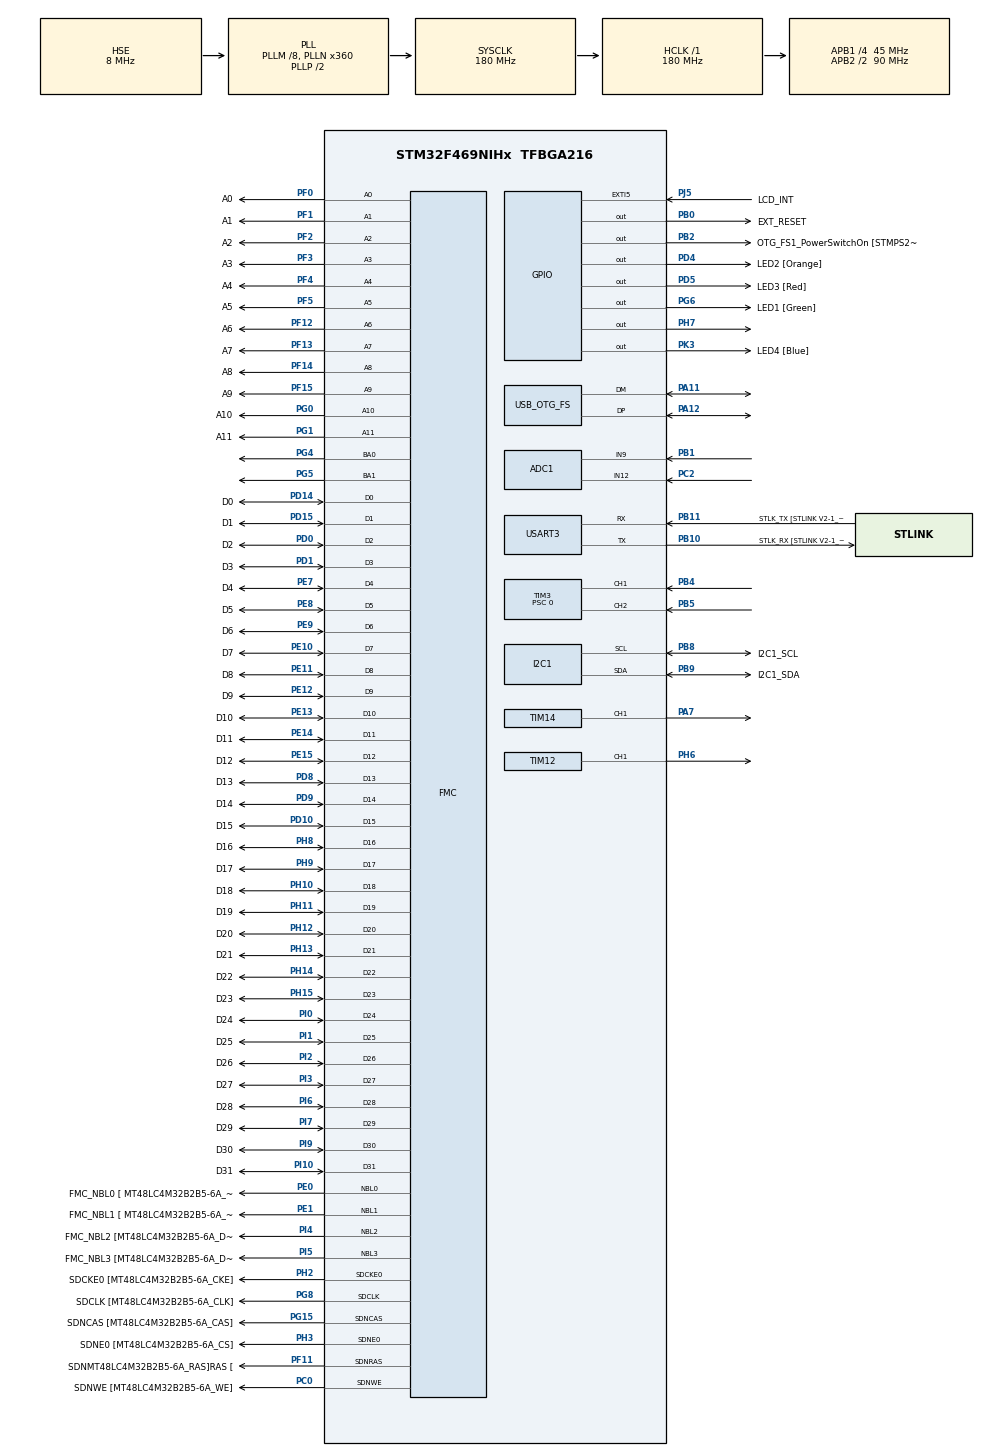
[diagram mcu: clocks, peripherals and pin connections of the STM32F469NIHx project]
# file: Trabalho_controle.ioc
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ADC1.Channel-0\#ChannelRegularConversion=ADC_CHANNEL_9
ADC1.Channel-1\#ChannelRegularConversion=ADC_CHANNEL_12
ADC1.ContinuousConvMode=ENABLE
ADC1.DMAContinuousRequests=ENABLE
ADC1.NbrOfConversion=2
ADC1.NbrOfConversionFlag=1
ADC1.Rank-0\#ChannelRegularConversion=1
ADC1.Rank-1\#ChannelRegularConversion=2
ADC1.SamplingTime-0\#ChannelRegularConversion=ADC_SAMPLETIME_480CYCLES
ADC1.SamplingTime-1\#ChannelRegularConversion=ADC_SAMPLETIME_480CYCLES
ADC1.ScanConvMode=ENABLE
ADC1.master=1
DMA2D.ColorMode=DMA2D_OUTPUT_RGB565
DSIHOST.BTA_FlowControl=__NULL
DSIHOST.ClockLaneHS2LPTime=35
DSIHOST.ClockLaneLP2HSTime=35
DSIHOST.DataLaneHS2LPTime=35
DSIHOST.DataLaneLP2HSTime=35
DSIHOST.LPCommandEnable=DSI_LP_COMMAND_ENABLE
DSIHOST.LPHorizontalBackPorchEnable=DSI_LP_HBP_ENABLE
DSIHOST.LPHorizontalFrontPorchEnable=DSI_LP_HFP_ENABLE
DSIHOST.LPLargestPacketSize=16
DSIHOST.LPVerticalActiveEnable=DSI_LP_VACT_ENABLE
DSIHOST.LPVerticalBackPorchEnable=DSI_LP_VBP_ENABLE
DSIHOST.LPVerticalFrontPorchEnable=DSI_LP_VFP_ENABLE
DSIHOST.LPVerticalSyncActiveEnable=DSI_LP_VSYNC_ENABLE
DSIHOST.Mode=DSI_VID_MODE_BURST
DSIHOST.NumberOfLanes=DSI_TWO_DATA_LANES
DSIHOST.PacketSize=800
DSIHOST.StopWaitTime=10
DSIHOST_CKN.GPIO_Label=DSI_CK_N
DSIHOST_CKN.Mode=DSIHost_Video
DSIHOST_CKN.Signal=DSIHOST_CKN
DSIHOST_CKP.GPIO_Label=DSI_CK_P
DSIHOST_CKP.Mode=DSIHost_Video
DSIHOST_CKP.Signal=DSIHOST_CKP
DSIHOST_D0N.GPIO_Label=DSI_D0_N
DSIHOST_D0N.Mode=DSIHost_Video
DSIHOST_D0N.Signal=DSIHOST_D0N
DSIHOST_D0P.GPIO_Label=DSI_D0_P
DSIHOST_D0P.Mode=DSIHost_Video
DSIHOST_D0P.Signal=DSIHOST_D0P
DSIHOST_D1N.GPIO_Label=DSI_D1_N
DSIHOST_D1N.Mode=DSIHost_Video
DSIHOST_D1N.Signal=DSIHOST_D1N
DSIHOST_D1P.GPIO_Label=DSI_D1_P
DSIHOST_D1P.Mode=DSIHost_Video
DSIHOST_D1P.Signal=DSIHOST_D1P
Dma.ADC1.1.Direction=DMA_PERIPH_TO_MEMORY
Dma.ADC1.1.FIFOMode=DMA_FIFOMODE_DISABLE
Dma.ADC1.1.Instance=DMA2_Stream4
Dma.ADC1.1.MemDataAlignment=DMA_MDATAALIGN_WORD
Dma.ADC1.1.MemInc=DMA_MINC_ENABLE
Dma.ADC1.1.Mode=DMA_CIRCULAR
Dma.ADC1.1.PeriphDataAlignment=DMA_PDATAALIGN_WORD
Dma.ADC1.1.PeriphInc=DMA_PINC_DISABLE
Dma.ADC1.1.Priority=DMA_PRIORITY_HIGH
Dma.MEMTOMEM.0.Direction=DMA_MEMORY_TO_MEMORY
Dma.MEMTOMEM.0.FIFOMode=DMA_FIFOMODE_ENABLE
Dma.MEMTOMEM.0.FIFOThreshold=DMA_FIFO_THRESHOLD_FULL
Dma.MEMTOMEM.0.Instance=DMA2_Stream0
Dma.MEMTOMEM.0.MemBurst=DMA_MBURST_SINGLE
Dma.MEMTOMEM.0.MemDataAlignment=DMA_MDATAALIGN_WORD
Dma.MEMTOMEM.0.MemInc=DMA_MINC_ENABLE
Dma.MEMTOMEM.0.Mode=DMA_NORMAL
Dma.MEMTOMEM.0.PeriphBurst=DMA_PBURST_SINGLE
Dma.MEMTOMEM.0.PeriphDataAlignment=DMA_PDATAALIGN_WORD
Dma.MEMTOMEM.0.PeriphInc=DMA_PINC_ENABLE
Dma.MEMTOMEM.0.Priority=DMA_PRIORITY_LOW
Dma.Request0=MEMTOMEM
Dma.Request1=ADC1
FMC.CASLatency1=FMC_SDRAM_CAS_LATENCY_3
FMC.ExitSelfRefreshDelay1=7
FMC.LoadToActiveDelay1=2
FMC.RCDDelay1=2
FMC.RPDelay1=2
FMC.RPDelay2=2
FMC.ReadBurst1=FMC_SDRAM_RBURST_ENABLE
FMC.ReadBurst2=FMC_SDRAM_RBURST_ENABLE
FMC.RowCycleDelay1=7
FMC.RowCycleDelay2=7
FMC.SDClockPeriod1=FMC_SDRAM_CLOCK_PERIOD_2
FMC.SDClockPeriod2=FMC_SDRAM_CLOCK_PERIOD_2
FMC.SelfRefreshTime1=4
FMC.WriteRecoveryTime1=3
LTDC.ActiveW=800
LTDC.Alpha_L0=255
LTDC.BlendingFactor1_L0=LTDC_BLENDING_FACTOR1_PAxCA
LTDC.BlendingFactor2_L0=LTDC_BLENDING_FACTOR2_PAxCA
LTDC.FBStartAdress_L0=0xC0000000
LTDC.HBP=34
LTDC.HFP=34
LTDC.HSPolarity=LTDC_HSPOLARITY_AH
LTDC.HSync=2
LTDC.ImageHeight_L0=480
LTDC.ImageWidth_L0=800
LTDC.Layers=0
LTDC.PixelFormat_L0=LTDC_PIXEL_FORMAT_RGB565
LTDC.VBP=150
LTDC.VFP=150
LTDC.VSPolarity=LTDC_VSPOLARITY_AH
LTDC.VSync=120
LTDC.WindowX1_L0=800
LTDC.WindowY1_L0=480
Mcu.Family=STM32F4
Mcu.Name=STM32F469NIHx
Mcu.Package=TFBGA216
NVIC.DMA2_Stream0_IRQn=true\:0\:0\:false\:false\:true\:true\:true\:true
NVIC.DMA2_Stream4_IRQn=true\:0\:0\:false\:false\:true\:false\:true\:true
NVIC.DSI_IRQn=true\:0\:0\:false\:false\:true\:true\:true\:true
NVIC.LTDC_IRQn=true\:0\:0\:false\:false\:true\:true\:true\:true
NVIC.OTG_FS_IRQn=true\:0\:0\:false\:false\:true\:false\:true\:true
NVIC.PriorityGroup=NVIC_PRIORITYGROUP_4
PA0/WKUP.GPIO_Label=WAKEUP [B2]
PA0/WKUP.Mode=SYS_WakeUp0
PA0/WKUP.Signal=SYS_WKUP
PA11.Mode=Device_Only
PA11.Signal=USB_OTG_FS_DM
PA12.Mode=Device_Only
PA12.Signal=USB_OTG_FS_DP
PA13.GPIO_Label=SWDIO
PA13.Mode=Serial_Wire
PA13.Signal=SYS_JTMS-SWDIO
PA14.GPIO_Label=SWCLK
PA14.Mode=Serial_Wire
PA14.Signal=SYS_JTCK-SWCLK
PA7.Signal=S_TIM14_CH1
PB0.GPIO_Label=EXT_RESET
PB0.GPIO_ModeDefaultOutputPP=GPIO_MODE_OUTPUT_PP
PB0.GPIO_PuPd=GPIO_NOPULL
PB0.GPIO_Speed=GPIO_SPEED_FREQ_LOW
PB0.Signal=GPIO_Output
PB1.Signal=ADCx_IN9
PB10.GPIO_Label=STLK_RX [STLINK V2-1_U2_RX]
PB10.GPIO_Mode=GPIO_MODE_AF_PP
PB10.GPIO_PuPd=GPIO_PULLUP
PB10.GPIO_Speed=GPIO_SPEED_FREQ_VERY_HIGH
PB10.Mode=Asynchronous
PB10.Signal=USART3_TX
PB11.GPIO_Label=STLK_TX [STLINK V2-1_U2_TX]
PB11.GPIO_Mode=GPIO_MODE_AF_PP
PB11.GPIO_PuPd=GPIO_PULLUP
PB11.GPIO_Speed=GPIO_SPEED_FREQ_VERY_HIGH
PB11.Mode=Asynchronous
PB11.Signal=USART3_RX
PB2/BOOT1.GPIO_Label=OTG_FS1_PowerSwitchOn [STMPS2151STR_En]
PB2/BOOT1.GPIO_ModeDefaultOutputPP=GPIO_MODE_OUTPUT_PP
PB2/BOOT1.GPIO_PuPd=GPIO_NOPULL
PB2/BOOT1.GPIO_Speed=GPIO_SPEED_FREQ_LOW
PB2/BOOT1.Signal=GPIO_Output
PB4.GPIO_PuPd=GPIO_NOPULL
PB4.GPIO_Speed=GPIO_SPEED_FREQ_VERY_HIGH
PB4.Signal=S_TIM3_CH1
PB5.GPIO_PuPd=GPIO_NOPULL
PB5.GPIO_Speed=GPIO_SPEED_FREQ_VERY_HIGH
PB5.Signal=S_TIM3_CH2
PB8.GPIO_Label=I2C1_SCL
PB8.GPIO_Mode=GPIO_MODE_AF_OD
PB8.GPIO_Pu=GPIO_PULLUP
PB8.GPIO_Speed=GPIO_SPEED_FREQ_VERY_HIGH
PB8.Mode=I2C
PB8.Signal=I2C1_SCL
PB9.GPIO_Label=I2C1_SDA
PB9.GPIO_Mode=GPIO_MODE_AF_OD
PB9.GPIO_Pu=GPIO_PULLUP
PB9.GPIO_Speed=GPIO_SPEED_FREQ_VERY_HIGH
PB9.Mode=I2C
PB9.Signal=I2C1_SDA
PC0.GPIO_Label=SDNWE [MT48LC4M32B2B5-6A_WE]
PC0.GPIO_Mode=GPIO_MODE_AF_PP
PC0.GPIO_PuPd=GPIO_NOPULL
PC0.GPIO_Speed_High_Default=GPIO_SPEED_FREQ_VERY_HIGH
PC0.Signal=FMC_SDNWE
PC14/OSC32_IN.Mode=LSE-External-Oscillator
PC14/OSC32_IN.Signal=RCC_OSC32_IN
PC15/OSC32_OUT.Mode=LSE-External-Oscillator
PC15/OSC32_OUT.Signal=RCC_OSC32_OUT
PC2.Signal=ADCx_IN12
PD0.GPIO_Label=D2
PD0.GPIO_Mode=GPIO_MODE_AF_PP
PD0.GPIO_PuPd=GPIO_NOPULL
PD0.GPIO_Speed_High_Default=GPIO_SPEED_FREQ_VERY_HIGH
PD0.Signal=FMC_D2_DA2
PD1.GPIO_Label=D3
PD1.GPIO_Mode=GPIO_MODE_AF_PP
PD1.GPIO_PuPd=GPIO_NOPULL
PD1.GPIO_Speed_High_Default=GPIO_SPEED_FREQ_VERY_HIGH
PD1.Signal=FMC_D3_DA3
PD10.GPIO_Label=D15
PD10.GPIO_Mode=GPIO_MODE_AF_PP
PD10.GPIO_PuPd=GPIO_NOPULL
PD10.GPIO_Speed_High_Default=GPIO_SPEED_FREQ_VERY_HIGH
PD10.Signal=FMC_D15_DA15
PD14.GPIO_Label=D0
PD14.GPIO_Mode=GPIO_MODE_AF_PP
PD14.GPIO_PuPd=GPIO_NOPULL
PD14.GPIO_Speed_High_Default=GPIO_SPEED_FREQ_VERY_HIGH
PD14.Signal=FMC_D0_DA0
PD15.GPIO_Label=D1
PD15.GPIO_Mode=GPIO_MODE_AF_PP
PD15.GPIO_PuPd=GPIO_NOPULL
PD15.GPIO_Speed_High_Default=GPIO_SPEED_FREQ_VERY_HIGH
PD15.Signal=FMC_D1_DA1
PD4.GPIO_Label=LED2 [Orange]
PD4.GPIO_ModeDefaultOutputPP=GPIO_MODE_OUTPUT_OD
PD4.GPIO_PuPd=GPIO_NOPULL
PD4.GPIO_Speed=GPIO_SPEED_FREQ_LOW
PD4.Signal=GPIO_Output
PD5.GPIO_Label=LED3 [Red]
PD5.GPIO_ModeDefaultOutputPP=GPIO_MODE_OUTPUT_OD
PD5.GPIO_PuPd=GPIO_NOPULL
PD5.GPIO_Speed=GPIO_SPEED_FREQ_LOW
PD5.Signal=GPIO_Output
PD8.GPIO_Label=D13
PD8.GPIO_Mode=GPIO_MODE_AF_PP
PD8.GPIO_PuPd=GPIO_NOPULL
PD8.GPIO_Speed_High_Default=GPIO_SPEED_FREQ_VERY_HIGH
PD8.Signal=FMC_D13_DA13
PD9.GPIO_Label=D14
PD9.GPIO_Mode=GPIO_MODE_AF_PP
PD9.GPIO_PuPd=GPIO_NOPULL
PD9.GPIO_Speed_High_Default=GPIO_SPEED_FREQ_VERY_HIGH
PD9.Signal=FMC_D14_DA14
PE0.GPIO_Label=FMC_NBL0 [ MT48LC4M32B2B5-6A_DQM0]
PE0.GPIO_Mode=GPIO_MODE_AF_PP
PE0.GPIO_PuPd=GPIO_NOPULL
PE0.GPIO_Speed_High_Default=GPIO_SPEED_FREQ_VERY_HIGH
PE0.Signal=FMC_NBL0
PE1.GPIO_Label=FMC_NBL1 [ MT48LC4M32B2B5-6A_DQM1]
PE1.GPIO_Mode=GPIO_MODE_AF_PP
PE1.GPIO_PuPd=GPIO_NOPULL
PE1.GPIO_Speed_High_Default=GPIO_SPEED_FREQ_VERY_HIGH
PE1.Signal=FMC_NBL1
PE10.GPIO_Label=D7
PE10.GPIO_Mode=GPIO_MODE_AF_PP
PE10.GPIO_PuPd=GPIO_NOPULL
PE10.GPIO_Speed_High_Default=GPIO_SPEED_FREQ_VERY_HIGH
PE10.Signal=FMC_D7_DA7
PE11.GPIO_Label=D8
PE11.GPIO_Mode=GPIO_MODE_AF_PP
PE11.GPIO_PuPd=GPIO_NOPULL
PE11.GPIO_Speed_High_Default=GPIO_SPEED_FREQ_VERY_HIGH
PE11.Signal=FMC_D8_DA8
PE12.GPIO_Label=D9
PE12.GPIO_Mode=GPIO_MODE_AF_PP
PE12.GPIO_PuPd=GPIO_NOPULL
PE12.GPIO_Speed_High_Default=GPIO_SPEED_FREQ_VERY_HIGH
PE12.Signal=FMC_D9_DA9
PE13.GPIO_Label=D10
PE13.GPIO_Mode=GPIO_MODE_AF_PP
PE13.GPIO_PuPd=GPIO_NOPULL
PE13.GPIO_Speed_High_Default=GPIO_SPEED_FREQ_VERY_HIGH
PE13.Signal=FMC_D10_DA10
PE14.GPIO_Label=D11
PE14.GPIO_Mode=GPIO_MODE_AF_PP
PE14.GPIO_PuPd=GPIO_NOPULL
PE14.GPIO_Speed_High_Default=GPIO_SPEED_FREQ_VERY_HIGH
PE14.Signal=FMC_D11_DA11
PE15.GPIO_Label=D12
PE15.GPIO_Mode=GPIO_MODE_AF_PP
PE15.GPIO_PuPd=GPIO_NOPULL
PE15.GPIO_Speed_High_Default=GPIO_SPEED_FREQ_VERY_HIGH
PE15.Signal=FMC_D12_DA12
PE7.GPIO_Label=D4
PE7.GPIO_Mode=GPIO_MODE_AF_PP
PE7.GPIO_PuPd=GPIO_NOPULL
PE7.GPIO_Speed_High_Default=GPIO_SPEED_FREQ_VERY_HIGH
PE7.Signal=FMC_D4_DA4
PE8.GPIO_Label=D5
PE8.GPIO_Mode=GPIO_MODE_AF_PP
PE8.GPIO_PuPd=GPIO_NOPULL
PE8.GPIO_Speed_High_Default=GPIO_SPEED_FREQ_VERY_HIGH
PE8.Signal=FMC_D5_DA5
PE9.GPIO_Label=D6
PE9.GPIO_Mode=GPIO_MODE_AF_PP
PE9.GPIO_PuPd=GPIO_NOPULL
PE9.GPIO_Speed_High_Default=GPIO_SPEED_FREQ_VERY_HIGH
PE9.Signal=FMC_D6_DA6
PF0.GPIO_Label=A0
PF0.GPIO_Mode=GPIO_MODE_AF_PP
PF0.GPIO_PuPd=GPIO_NOPULL
PF0.GPIO_Speed_High_Default=GPIO_SPEED_FREQ_VERY_HIGH
PF0.Signal=FMC_A0
PF1.GPIO_Label=A1
PF1.GPIO_Mode=GPIO_MODE_AF_PP
PF1.GPIO_PuPd=GPIO_NOPULL
PF1.GPIO_Speed_High_Default=GPIO_SPEED_FREQ_VERY_HIGH
PF1.Signal=FMC_A1
PF11.GPIO_Label=SDNMT48LC4M32B2B5-6A_RAS]RAS [
PF11.GPIO_Mode=GPIO_MODE_AF_PP
PF11.GPIO_PuPd=GPIO_NOPULL
PF11.GPIO_Speed_High_Default=GPIO_SPEED_FREQ_VERY_HIGH
PF11.Signal=FMC_SDNRAS
PF12.GPIO_Label=A6
PF12.GPIO_Mode=GPIO_MODE_AF_PP
PF12.GPIO_PuPd=GPIO_NOPULL
PF12.GPIO_Speed_High_Default=GPIO_SPEED_FREQ_VERY_HIGH
PF12.Signal=FMC_A6
PF13.GPIO_Label=A7
PF13.GPIO_Mode=GPIO_MODE_AF_PP
PF13.GPIO_PuPd=GPIO_NOPULL
PF13.GPIO_Speed_High_Default=GPIO_SPEED_FREQ_VERY_HIGH
PF13.Signal=FMC_A7
PF14.GPIO_Label=A8
PF14.GPIO_Mode=GPIO_MODE_AF_PP
PF14.GPIO_PuPd=GPIO_NOPULL
PF14.GPIO_Speed_High_Default=GPIO_SPEED_FREQ_VERY_HIGH
PF14.Signal=FMC_A8
PF15.GPIO_Label=A9
PF15.GPIO_Mode=GPIO_MODE_AF_PP
PF15.GPIO_PuPd=GPIO_NOPULL
PF15.GPIO_Speed_High_Default=GPIO_SPEED_FREQ_VERY_HIGH
PF15.Signal=FMC_A9
PF2.GPIO_Label=A2
PF2.GPIO_Mode=GPIO_MODE_AF_PP
PF2.GPIO_PuPd=GPIO_NOPULL
PF2.GPIO_Speed_High_Default=GPIO_SPEED_FREQ_VERY_HIGH
PF2.Signal=FMC_A2
PF3.GPIO_Label=A3
PF3.GPIO_Mode=GPIO_MODE_AF_PP
PF3.GPIO_PuPd=GPIO_NOPULL
PF3.GPIO_Speed_High_Default=GPIO_SPEED_FREQ_VERY_HIGH
PF3.Signal=FMC_A3
PF4.GPIO_Label=A4
PF4.GPIO_Mode=GPIO_MODE_AF_PP
PF4.GPIO_PuPd=GPIO_NOPULL
PF4.GPIO_Speed_High_Default=GPIO_SPEED_FREQ_VERY_HIGH
PF4.Signal=FMC_A4
PF5.GPIO_Label=A5
PF5.GPIO_Mode=GPIO_MODE_AF_PP
PF5.GPIO_PuPd=GPIO_NOPULL
PF5.GPIO_Speed_High_Default=GPIO_SPEED_FREQ_VERY_HIGH
PF5.Signal=FMC_A5
PG0.GPIO_Label=A10
PG0.GPIO_Mode=GPIO_MODE_AF_PP
PG0.GPIO_PuPd=GPIO_NOPULL
PG0.GPIO_Speed_High_Default=GPIO_SPEED_FREQ_VERY_HIGH
PG0.Signal=FMC_A10
PG1.GPIO_Label=A11
PG1.GPIO_Mode=GPIO_MODE_AF_PP
PG1.GPIO_PuPd=GPIO_NOPULL
PG1.GPIO_Speed_High_Default=GPIO_SPEED_FREQ_VERY_HIGH
PG1.Signal=FMC_A11
PG15.GPIO_Label=SDNCAS [MT48LC4M32B2B5-6A_CAS]
PG15.GPIO_Mode=GPIO_MODE_AF_PP
PG15.GPIO_PuPd=GPIO_NOPULL
PG15.GPIO_Speed_High_Default=GPIO_SPEED_FREQ_VERY_HIGH
PG15.Signal=FMC_SDNCAS
PG4.Signal=FMC_A14_BA0
PG5.Signal=FMC_A15_BA1
PG6.GPIO_Label=LED1 [Green]
PG6.GPIO_ModeDefaultOutputPP=GPIO_MODE_OUTPUT_OD
PG6.GPIO_PuPd=GPIO_NOPULL
PG6.GPIO_Speed=GPIO_SPEED_FREQ_LOW
PG6.Signal=GPIO_Output
PG8.GPIO_Label=SDCLK [MT48LC4M32B2B5-6A_CLK]
PG8.GPIO_Mode=GPIO_MODE_AF_PP
PG8.GPIO_PuPd=GPIO_NOPULL
PG8.GPIO_Speed_High_Default=GPIO_SPEED_FREQ_VERY_HIGH
PG8.Signal=FMC_SDCLK
PH0/OSC_IN.Mode=HSE-External-Oscillator
PH0/OSC_IN.Signal=RCC_OSC_IN
PH1/OSC_OUT.Mode=HSE-External-Oscillator
PH1/OSC_OUT.Signal=RCC_OSC_OUT
PH10.GPIO_Label=D18
PH10.GPIO_Mode=GPIO_MODE_AF_PP
PH10.GPIO_PuPd=GPIO_NOPULL
PH10.GPIO_Speed_High_Default=GPIO_SPEED_FREQ_VERY_HIGH
PH10.Signal=FMC_D18
PH11.GPIO_Label=D19
PH11.GPIO_Mode=GPIO_MODE_AF_PP
PH11.GPIO_PuPd=GPIO_NOPULL
PH11.GPIO_Speed_High_Default=GPIO_SPEED_FREQ_VERY_HIGH
PH11.Signal=FMC_D19
PH12.GPIO_Label=D20
PH12.GPIO_Mode=GPIO_MODE_AF_PP
PH12.GPIO_PuPd=GPIO_NOPULL
PH12.GPIO_Speed_High_Default=GPIO_SPEED_FREQ_VERY_HIGH
PH12.Signal=FMC_D20
PH13.GPIO_Label=D21
PH13.GPIO_Mode=GPIO_MODE_AF_PP
PH13.GPIO_PuPd=GPIO_NOPULL
PH13.GPIO_Speed_High_Default=GPIO_SPEED_FREQ_VERY_HIGH
PH13.Signal=FMC_D21
PH14.GPIO_Label=D22
PH14.GPIO_Mode=GPIO_MODE_AF_PP
PH14.GPIO_PuPd=GPIO_NOPULL
PH14.GPIO_Speed_High_Default=GPIO_SPEED_FREQ_VERY_HIGH
PH14.Signal=FMC_D22
PH15.GPIO_Label=D23
PH15.GPIO_Mode=GPIO_MODE_AF_PP
PH15.GPIO_PuPd=GPIO_NOPULL
PH15.GPIO_Speed_High_Default=GPIO_SPEED_FREQ_VERY_HIGH
PH15.Signal=FMC_D23
PH2.GPIO_Label=SDCKE0 [MT48LC4M32B2B5-6A_CKE]
PH2.GPIO_Mode=GPIO_MODE_AF_PP
PH2.GPIO_PuPd=GPIO_NOPULL
PH2.GPIO_Speed_High_Default=GPIO_SPEED_FREQ_VERY_HIGH
PH2.Mode=SdramChipSelect1_1
PH2.Signal=FMC_SDCKE0
PH3.GPIO_Label=SDNE0 [MT48LC4M32B2B5-6A_CS]
PH3.GPIO_Mode=GPIO_MODE_AF_PP
PH3.GPIO_PuPd=GPIO_NOPULL
PH3.GPIO_Speed_High_Default=GPIO_SPEED_FREQ_VERY_HIGH
PH3.Mode=SdramChipSelect1_1
PH3.Signal=FMC_SDNE0
PH6.Signal=S_TIM12_CH1
PH7.Signal=GPIO_Output
PH8.GPIO_Label=D16
PH8.GPIO_Mode=GPIO_MODE_AF_PP
PH8.GPIO_PuPd=GPIO_NOPULL
PH8.GPIO_Speed_High_Default=GPIO_SPEED_FREQ_VERY_HIGH
PH8.Signal=FMC_D16
PH9.GPIO_Label=D17
PH9.GPIO_Mode=GPIO_MODE_AF_PP
PH9.GPIO_PuPd=GPIO_NOPULL
PH9.GPIO_Speed_High_Default=GPIO_SPEED_FREQ_VERY_HIGH
PH9.Signal=FMC_D17
PI0.GPIO_Label=D24
PI0.GPIO_Mode=GPIO_MODE_AF_PP
PI0.GPIO_PuPd=GPIO_NOPULL
PI0.GPIO_Speed_High_Default=GPIO_SPEED_FREQ_VERY_HIGH
PI0.Signal=FMC_D24
PI1.GPIO_Label=D25
PI1.GPIO_Mode=GPIO_MODE_AF_PP
PI1.GPIO_PuPd=GPIO_NOPULL
PI1.GPIO_Speed_High_Default=GPIO_SPEED_FREQ_VERY_HIGH
PI1.Signal=FMC_D25
PI10.GPIO_Label=D31
PI10.GPIO_Mode=GPIO_MODE_AF_PP
PI10.GPIO_PuPd=GPIO_NOPULL
PI10.GPIO_Speed_High_Default=GPIO_SPEED_FREQ_VERY_HIGH
PI10.Signal=FMC_D31
PI2.GPIO_Label=D26
PI2.GPIO_Mode=GPIO_MODE_AF_PP
PI2.GPIO_PuPd=GPIO_NOPULL
PI2.GPIO_Speed_High_Default=GPIO_SPEED_FREQ_VERY_HIGH
PI2.Signal=FMC_D26
PI3.GPIO_Label=D27
PI3.GPIO_Mode=GPIO_MODE_AF_PP
PI3.GPIO_PuPd=GPIO_NOPULL
PI3.GPIO_Speed_High_Default=GPIO_SPEED_FREQ_VERY_HIGH
PI3.Signal=FMC_D27
PI4.GPIO_Label=FMC_NBL2 [MT48LC4M32B2B5-6A_DQM2]
PI4.GPIO_Mode=GPIO_MODE_AF_PP
PI4.GPIO_PuPd=GPIO_NOPULL
PI4.GPIO_Speed_High_Default=GPIO_SPEED_FREQ_VERY_HIGH
PI4.Signal=FMC_NBL2
PI5.GPIO_Label=FMC_NBL3 [MT48LC4M32B2B5-6A_DQM3]
PI5.GPIO_Mode=GPIO_MODE_AF_PP
PI5.GPIO_PuPd=GPIO_NOPULL
PI5.GPIO_Speed_High_Default=GPIO_SPEED_FREQ_VERY_HIGH
PI5.Signal=FMC_NBL3
PI6.GPIO_Label=D28
PI6.GPIO_Mode=GPIO_MODE_AF_PP
PI6.GPIO_PuPd=GPIO_NOPULL
PI6.GPIO_Speed_High_Default=GPIO_SPEED_FREQ_VERY_HIGH
PI6.Signal=FMC_D28
PI7.GPIO_Label=D29
PI7.GPIO_Mode=GPIO_MODE_AF_PP
PI7.GPIO_PuPd=GPIO_NOPULL
PI7.GPIO_Speed_High_Default=GPIO_SPEED_FREQ_VERY_HIGH
PI7.Signal=FMC_D29
PI9.GPIO_Label=D30
PI9.GPIO_Mode=GPIO_MODE_AF_PP
PI9.GPIO_PuPd=GPIO_NOPULL
PI9.GPIO_Speed_High_Default=GPIO_SPEED_FREQ_VERY_HIGH
PI9.Signal=FMC_D30
PJ2.GPIO_Label=DSI_TE
PJ2.GPIO_Mode=GPIO_MODE_AF_PP
PJ2.GPIO_PuPd=GPIO_NOPULL
PJ2.GPIO_Speed=GPIO_SPEED_FREQ_VERY_HIGH
PJ2.Signal=DSIHOST_TE
PJ5.GPIO_Label=LCD_INT
PJ5.GPIO_ModeDefaultEXTI=GPIO_MODE_IT_RISING
PJ5.GPIO_PuPd=GPIO_NOPULL
PJ5.Signal=GPXTI5
PK3.GPIO_Label=LED4 [Blue]
PK3.GPIO_ModeDefaultOutputPP=GPIO_MODE_OUTPUT_OD
PK3.GPIO_PuPd=GPIO_NOPULL
PK3.GPIO_Speed=GPIO_SPEED_FREQ_LOW
PK3.Signal=GPIO_Output
ProjectManager.HeapSize=0x200
ProjectManager.StackSize=0x400
ProjectManager.TargetToolchain=STM32CubeIDE
RCC.AHBFreq_Value=180000000
RCC.APB1CLKDivider=RCC_HCLK_DIV4
RCC.APB1Freq_Value=45000000
RCC.APB1TimFreq_Value=90000000
RCC.APB2CLKDivider=RCC_HCLK_DIV2
RCC.APB2Freq_Value=90000000
RCC.APB2TimFreq_Value=180000000
RCC.CortexFreq_Value=180000000
RCC.HCLKFreq_Value=180000000
RCC.HSE_VALUE=8000000
RCC.PLLDSIIDF=DSI_PLL_IN_DIV2
RCC.PLLDSINDIV=125
RCC.PLLM=8
RCC.PLLN=360
RCC.PLLQ=6
RCC.PLLR=6
RCC.PLLSAIN=384
RCC.PLLSAIP=RCC_PLLSAIP_DIV8
RCC.PLLSAIQ=2
RCC.PLLSAIR=7
RCC.PLLSourceVirtual=RCC_PLLSOURCE_HSE
RCC.SYSCLKFreq_VALUE=180000000
RCC.SYSCLKSource=RCC_SYSCLKSOURCE_PLLCLK
RCC.USBCLockSelection=RCC_CLK48CLKSOURCE_PLLSAIP
RCC.USBFreq_Value=48000000
RCC.VCOOutputFreq_Value=360000000
SH.ADCx_IN12.0=ADC1_IN12,IN12
SH.ADCx_IN9.0=ADC1_IN9,IN9
SH.FMC_A0.0=FMC_A0,12b-sda1
SH.FMC_A1.0=FMC_A1,12b-sda1
SH.FMC_A10.0=FMC_A10,12b-sda1
SH.FMC_A11.0=FMC_A11,12b-sda1
SH.FMC_A14_BA0.0=FMC_BA0,FourSdramBanks1
SH.FMC_A15_BA1.0=FMC_BA1,FourSdramBanks1
SH.FMC_A2.0=FMC_A2,12b-sda1
SH.FMC_A3.0=FMC_A3,12b-sda1
SH.FMC_A4.0=FMC_A4,12b-sda1
SH.FMC_A5.0=FMC_A5,12b-sda1
SH.FMC_A6.0=FMC_A6,12b-sda1
SH.FMC_A7.0=FMC_A7,12b-sda1
SH.FMC_A8.0=FMC_A8,12b-sda1
SH.FMC_A9.0=FMC_A9,12b-sda1
SH.FMC_D0_DA0.0=FMC_D0,sd-32b-d1
SH.FMC_D10_DA10.0=FMC_D10,sd-32b-d1
SH.FMC_D11_DA11.0=FMC_D11,sd-32b-d1
SH.FMC_D12_DA12.0=FMC_D12,sd-32b-d1
SH.FMC_D13_DA13.0=FMC_D13,sd-32b-d1
SH.FMC_D14_DA14.0=FMC_D14,sd-32b-d1
SH.FMC_D15_DA15.0=FMC_D15,sd-32b-d1
SH.FMC_D16.0=FMC_D16,sd-32b-d1
SH.FMC_D17.0=FMC_D17,sd-32b-d1
SH.FMC_D18.0=FMC_D18,sd-32b-d1
SH.FMC_D19.0=FMC_D19,sd-32b-d1
SH.FMC_D1_DA1.0=FMC_D1,sd-32b-d1
SH.FMC_D20.0=FMC_D20,sd-32b-d1
SH.FMC_D21.0=FMC_D21,sd-32b-d1
SH.FMC_D22.0=FMC_D22,sd-32b-d1
SH.FMC_D23.0=FMC_D23,sd-32b-d1
SH.FMC_D24.0=FMC_D24,sd-32b-d1
SH.FMC_D25.0=FMC_D25,sd-32b-d1
SH.FMC_D26.0=FMC_D26,sd-32b-d1
SH.FMC_D27.0=FMC_D27,sd-32b-d1
SH.FMC_D28.0=FMC_D28,sd-32b-d1
SH.FMC_D29.0=FMC_D29,sd-32b-d1
SH.FMC_D2_DA2.0=FMC_D2,sd-32b-d1
SH.FMC_D30.0=FMC_D30,sd-32b-d1
SH.FMC_D31.0=FMC_D31,sd-32b-d1
SH.FMC_D3_DA3.0=FMC_D3,sd-32b-d1
SH.FMC_D4_DA4.0=FMC_D4,sd-32b-d1
SH.FMC_D5_DA5.0=FMC_D5,sd-32b-d1
SH.FMC_D6_DA6.0=FMC_D6,sd-32b-d1
SH.FMC_D7_DA7.0=FMC_D7,sd-32b-d1
SH.FMC_D8_DA8.0=FMC_D8,sd-32b-d1
SH.FMC_D9_DA9.0=FMC_D9,sd-32b-d1
SH.FMC_NBL0.0=FMC_NBL0,Sd4ByteEnable1
SH.FMC_NBL1.0=FMC_NBL1,Sd4ByteEnable1
SH.FMC_NBL2.0=FMC_NBL2,Sd4ByteEnable1
SH.FMC_NBL3.0=FMC_NBL3,Sd4ByteEnable1
SH.FMC_SDCLK.0=FMC_SDCLK,12b-sda1
SH.FMC_SDNCAS.0=FMC_SDNCAS,12b-sda1
SH.FMC_SDNRAS.0=FMC_SDNRAS,12b-sda1
SH.FMC_SDNWE.0=FMC_SDNWE,12b-sda1
SH.S_TIM12_CH1.0=TIM12_CH1,PWM Generation1 CH1
SH.S_TIM14_CH1.0=TIM14_CH1,PWM Generation1 CH1
SH.S_TIM3_CH1.0=TIM3_CH1,Encoder_Interface
SH.S_TIM3_CH2.0=TIM3_CH2,Encoder_Interface
TIM12.Channel-PWM\ Generation1\ CH1=TIM_CHANNEL_1
TIM12.Period=4096
TIM12.Prescaler=99
TIM14.Channel=TIM_CHANNEL_1
TIM14.Period=4069
TIM14.Prescaler=99
TIM3.EncoderMode=TIM_ENCODERMODE_TI12
TIM3.IC1Polarity=TIM_ICPOLARITY_RISING
TIM3.IC2Polarity=TIM_ICPOLARITY_RISING
TIM3.Prescaler=0
USART3.VirtualMode=VM_ASYNC
USB_DEVICE.CLASS_NAME_FS=CDC
USB_DEVICE.VirtualMode-CDC_FS=Cdc
USB_DEVICE.VirtualModeFS=Cdc_FS
USB_OTG_FS.VirtualMode=Device_Only
VP_DMA2D_VS_DMA2D.Mode=DMA2D_Activate
VP_LTDC_DSIMode.Mode=RGB565
VP_TIM12_VS_ClockSourceINT.Mode=Internal
VP_TIM14_VS_ClockSourceINT.Mode=Enable_Timer
VP_TIM5_VS_ClockSourceINT.Mode=Internal
VP_USB_DEVICE_VS_USB_DEVICE_CDC_FS.Mode=CDC_FS
board=STM32F469I-DISCO

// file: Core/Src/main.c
/* USER CODE BEGIN Header */
/**
 ******************************************************************************
 * @file           : main.c
 * @brief          : Main program body
 ******************************************************************************
 * @attention
 *
 * Copyright (c) 2023 STMicroelectronics.
 * All rights reserved.
 *
 * This software is licensed under terms that can be found in the LICENSE file
 * in the root directory of this software component.
 * If no LICENSE file comes with this software, it is provided AS-IS.
 *
 ******************************************************************************
 */
/* USER CODE END Header */
#include "main.h"
#include "usb_device.h"

/* USER CODE BEGIN Includes */
#include <stdlib.h>
#include <stdio.h>
#include <string.h>
#include <lvgl.h>
#include <screen_driver.h>
#include <touch_sensor_driver.h>
#include "usbd_cdc_if.h"
#include <math.h>
/* USER CODE END Includes */

/* USER CODE BEGIN PD */
#define USE_FULL_ASSERT
/**
 * @brief  FMC SDRAM Mode definition register defines
 *
 * @brief  defines copied from the STM32F469I-Disco Board support package
 */
#define SDRAM_MODEREG_BURST_LENGTH_1             ((uint16_t)0x0000)
#define SDRAM_MODEREG_BURST_LENGTH_2             ((uint16_t)0x0001)
#define SDRAM_MODEREG_BURST_LENGTH_4             ((uint16_t)0x0002)
#define SDRAM_MODEREG_BURST_LENGTH_8             ((uint16_t)0x0004)
#define SDRAM_MODEREG_BURST_TYPE_SEQUENTIAL      ((uint16_t)0x0000)
#define SDRAM_MODEREG_BURST_TYPE_INTERLEAVED     ((uint16_t)0x0008)
#define SDRAM_MODEREG_CAS_LATENCY_2              ((uint16_t)0x0020)
#define SDRAM_MODEREG_CAS_LATENCY_3              ((uint16_t)0x0030)
#define SDRAM_MODEREG_OPERATING_MODE_STANDARD    ((uint16_t)0x0000)
#define SDRAM_MODEREG_WRITEBURST_MODE_PROGRAMMED ((uint16_t)0x0000)
#define SDRAM_MODEREG_WRITEBURST_MODE_SINGLE     ((uint16_t)0x0200)

/**
 * @brief  SDRAM refresh counter (90 MHz SD clock)
 *
 * @brief  defines copied from the STM32F469I-Disco Board support package
 */
#define REFRESH_COUNT       ((uint32_t)0x0569)
#define SDRAM_TIMEOUT       ((uint32_t)0xFFFF)

#define ENC_PPR 			1600
#define ENC_PULSE_RAD 		(M_TWOPI/ENC_PPR)
#define ENC_MENSURE_TIME_S	0.1
#define ENC_D				(ENC_PPR * ENC_MENSURE_TIME_S)

/* USER CODE END PD */

ADC_HandleTypeDef hadc1;
DMA_HandleTypeDef hdma_adc1;

DMA2D_HandleTypeDef hdma2d;

DSI_HandleTypeDef hdsi;

I2C_HandleTypeDef hi2c1;

LTDC_HandleTypeDef hltdc;

TIM_HandleTypeDef htim3;
TIM_HandleTypeDef htim5;
TIM_HandleTypeDef htim12;
TIM_HandleTypeDef htim14;

UART_HandleTypeDef huart3;

DMA_HandleTypeDef hdma_memtomem_dma2_stream0;
SDRAM_HandleTypeDef hsdram1;

/* USER CODE BEGIN PV */

static volatile uint32_t enc_cnt_cw_total = 0;
static volatile uint32_t enc_cnt_ccw_total = 0;
static volatile uint16_t enc_pulses_old = 0;
static volatile int16_t enc_pulses_diff = 0;
static volatile double AngularVelocity = 0.0;
static volatile double Frequency = 0.0;
static volatile double RPM = 0.0;

static volatile double kP = 1.0;
static volatile double kI = 0.0;
static volatile double kD = 0.0;
static volatile double P = 0.0;
static volatile double I = 0.0;
static volatile double D = 0.0;
static volatile double PID = 0.0;

static double setPoint 	= 0.0;
static volatile double error 	= 0.0;
static volatile double lastRPM	= 0.0;

static volatile char string[32];

/* USER CODE END PV */

void SystemClock_Config(void);
void PeriphCommonClock_Config(void);
static void MX_GPIO_Init(void);
static void MX_DMA_Init(void);
static void MX_DMA2D_Init(void);
static void MX_DSIHOST_DSI_Init(void);
static void MX_FMC_Init(void);
static void MX_I2C1_Init(void);
static void MX_LTDC_Init(void);
static void MX_USART3_UART_Init(void);
static void MX_TIM3_Init(void);
static void MX_TIM12_Init(void);
static void MX_TIM14_Init(void);
static void MX_TIM5_Init(void);
static void MX_ADC1_Init(void);
/* USER CODE BEGIN PFP */
void create_gui(void);
/* USER CODE END PFP */

/* USER CODE BEGIN 0 */

/**
 * @brief Função de interrupção do TIMER 5
 * @details Ocerre a cada 100 milisegundos
 */
void TIM5_IRQHandler(void)
{
	if (TIM5->SR & (TIM_SR_UIF))
	{
		// Limpa a flag de interrupção
		TIM5->SR &= ~(TIM_SR_UIF);
		// Pega a quantidade de pulsos do encder
		uint16_t counter_value = TIM3->CNT;
		// Calcula a diferença entre o valor atual e o último valor lido
		enc_pulses_diff = counter_value - enc_pulses_old;
		// Atualiza o último lido
		enc_pulses_old = counter_value;
		// Calcula a velocidade angular, frequencia e RPM
		AngularVelocity = (M_TWOPI * enc_pulses_diff) / ENC_D;
		Frequency = AngularVelocity / M_TWOPI;
		RPM = Frequency * 60.0;
		/* Implementação do controle PID */
		// Calcula o erro
		error = setPoint - RPM;
		// Calcula a proporcional
		P = error * kP;
		// Calcula a itegral
		I += error * kI * ( /* 100ms */0.1) ;
		// Calcula a derivada
		D = (lastRPM - RPM) * kD * ( /* 100ms */0.1);
		// Soma os parâmetros
		PID = P + I + D;
		// Seta o duty cycle do PWM com o valor calculado do PID
		TIM14->CCR1 = (uint16_t)PID;
		/* Cria uma linha de texto contendo "tempo em segundos, rotação em RPM" */
		size_t l = sprintf(string, "$%0.3f %0.3f;", RPM, setPoint);
		/* Transmite via usb a linha gerada para o supervisório */
		CDC_Transmit_FS((uint8_t*)string, l);
	}
	NVIC_ClearPendingIRQ(TIM5_IRQn);
}

uint32_t ADC_DATA[2];
float mA1, mA2;

/* USER CODE END 0 */

int main(void)
{

  /* MCU Configuration--------------------------------------------------------*/

  /* Reset of all peripherals, Initializes the Flash interface and the Systick. */
  HAL_Init();

  /* Configure the system clock */
  SystemClock_Config();

/* Configure the peripherals common clocks */
  PeriphCommonClock_Config();

  /* Initialize all configured peripherals */
  MX_GPIO_Init();
  MX_DMA_Init();
  MX_DMA2D_Init();
  MX_DSIHOST_DSI_Init();
  MX_FMC_Init();
  MX_I2C1_Init();
  MX_LTDC_Init();
  MX_USART3_UART_Init();
  MX_TIM3_Init();
  MX_TIM12_Init();
  MX_TIM14_Init();
  MX_TIM5_Init();
  MX_USB_DEVICE_Init();
  MX_ADC1_Init();
  /* USER CODE BEGIN 2 */

	lv_init();
	screen_driver_init();
	touch_sensor_driver_init();
	create_gui();

	HAL_ADC_Start_DMA(&hadc1, ADC_DATA, 2);

//	HAL_TIM_Encoder_Start(&htim3, TIM_CHANNEL_ALL);
//	HAL_TIM_PWM_Start(&htim12, TIM_CHANNEL_1);
//	HAL_TIM_PWM_Start(&htim14, TIM_CHANNEL_1);
//
//	HAL_Delay(2000);

	/* Configura o timer 5 para gerar interrupção a cada 5 ms.
	 * Na interrupção será calculado o RPM. */
//	TIM5->PSC   = 90-1; 		//
//	TIM5->ARR   = 100000-1;
//	TIM5->RCR   =  0;
//	TIM5->DIER  = TIM_DIER_UIE;
//	NVIC_EnableIRQ(TIM5_IRQn);
//	TIM5->CR1  |= TIM_CR1_CEN; Is = (Vout x 1k) / (RS x RL)

  /* USER CODE END 2 */

  /* Infinite loop */
  /* USER CODE BEGIN WHILE */
	while (1)
	{
		lv_timer_handler();
    /* USER CODE END WHILE */

	}
}

void SystemClock_Config(void)
{
  RCC_OscInitTypeDef RCC_OscInitStruct = {0};
  RCC_ClkInitTypeDef RCC_ClkInitStruct = {0};

  /** Configure the main internal regulator output voltage
  */
  __HAL_RCC_PWR_CLK_ENABLE();
  __HAL_PWR_VOLTAGESCALING_CONFIG(PWR_REGULATOR_VOLTAGE_SCALE1);

  /** Initializes the RCC Oscillators according to the specified parameters
  * in the RCC_OscInitTypeDef structure.
  */
  RCC_OscInitStruct.OscillatorType = RCC_OSCILLATORTYPE_HSE;
  RCC_OscInitStruct.HSEState = RCC_HSE_ON;
  RCC_OscInitStruct.PLL.PLLState = RCC_PLL_ON;
  RCC_OscInitStruct.PLL.PLLSource = RCC_PLLSOURCE_HSE;
  RCC_OscInitStruct.PLL.PLLM = 8;
  RCC_OscInitStruct.PLL.PLLN = 360;
  RCC_OscInitStruct.PLL.PLLP = RCC_PLLP_DIV2;
  RCC_OscInitStruct.PLL.PLLQ = 6;
  RCC_OscInitStruct.PLL.PLLR = 6;
  if (HAL_RCC_OscConfig(&RCC_OscInitStruct) != HAL_OK)
  {
    Error_Handler();
  }

  /** Activate the Over-Drive mode
  */
  if (HAL_PWREx_EnableOverDrive() != HAL_OK)
  {
    Error_Handler();
  }

  /** Initializes the CPU, AHB and APB buses clocks
  */
  RCC_ClkInitStruct.ClockType = RCC_CLOCKTYPE_HCLK|RCC_CLOCKTYPE_SYSCLK
                              |RCC_CLOCKTYPE_PCLK1|RCC_CLOCKTYPE_PCLK2;
  RCC_ClkInitStruct.SYSCLKSource = RCC_SYSCLKSOURCE_PLLCLK;
  RCC_ClkInitStruct.AHBCLKDivider = RCC_SYSCLK_DIV1;
  RCC_ClkInitStruct.APB1CLKDivider = RCC_HCLK_DIV4;
  RCC_ClkInitStruct.APB2CLKDivider = RCC_HCLK_DIV2;

  if (HAL_RCC_ClockConfig(&RCC_ClkInitStruct, FLASH_LATENCY_5) != HAL_OK)
  {
    Error_Handler();
  }
}

void PeriphCommonClock_Config(void)
{
  RCC_PeriphCLKInitTypeDef PeriphClkInitStruct = {0};

  /** Initializes the peripherals clock
  */
  PeriphClkInitStruct.PeriphClockSelection = RCC_PERIPHCLK_CLK48|RCC_PERIPHCLK_LTDC;
  PeriphClkInitStruct.PLLSAI.PLLSAIN = 384;
  PeriphClkInitStruct.PLLSAI.PLLSAIR = 7;
  PeriphClkInitStruct.PLLSAI.PLLSAIP = RCC_PLLSAIP_DIV8;
  PeriphClkInitStruct.PLLSAIDivR = RCC_PLLSAIDIVR_2;
  PeriphClkInitStruct.Clk48ClockSelection = RCC_CLK48CLKSOURCE_PLLSAIP;
  if (HAL_RCCEx_PeriphCLKConfig(&PeriphClkInitStruct) != HAL_OK)
  {
    Error_Handler();
  }
}

static void MX_ADC1_Init(void)
{

  ADC_ChannelConfTypeDef sConfig = {0};

  /** Configure the global features of the ADC (Clock, Resolution, Data Alignment and number of conversion)
  */
  hadc1.Instance = ADC1;
  hadc1.Init.ClockPrescaler = ADC_CLOCK_SYNC_PCLK_DIV4;
  hadc1.Init.Resolution = ADC_RESOLUTION_12B;
  hadc1.Init.ScanConvMode = ENABLE;
  hadc1.Init.ContinuousConvMode = ENABLE;
  hadc1.Init.DiscontinuousConvMode = DISABLE;
  hadc1.Init.ExternalTrigConvEdge = ADC_EXTERNALTRIGCONVEDGE_NONE;
  hadc1.Init.ExternalTrigConv = ADC_SOFTWARE_START;
  hadc1.Init.DataAlign = ADC_DATAALIGN_RIGHT;
  hadc1.Init.NbrOfConversion = 2;
  hadc1.Init.DMAContinuousRequests = ENABLE;
  hadc1.Init.EOCSelection = ADC_EOC_SINGLE_CONV;
  if (HAL_ADC_Init(&hadc1) != HAL_OK)
  {
    Error_Handler();
  }

  /** Configure for the selected ADC regular channel its corresponding rank in the sequencer and its sample time.
  */
  sConfig.Channel = ADC_CHANNEL_9;
  sConfig.Rank = 1;
  sConfig.SamplingTime = ADC_SAMPLETIME_480CYCLES;
  if (HAL_ADC_ConfigChannel(&hadc1, &sConfig) != HAL_OK)
  {
    Error_Handler();
  }

  /** Configure for the selected ADC regular channel its corresponding rank in the sequencer and its sample time.
  */
  sConfig.Channel = ADC_CHANNEL_12;
  sConfig.Rank = 2;
  if (HAL_ADC_ConfigChannel(&hadc1, &sConfig) != HAL_OK)
  {
    Error_Handler();
  }

}

static void MX_DMA2D_Init(void)
{

  hdma2d.Instance = DMA2D;
  hdma2d.Init.Mode = DMA2D_M2M;
  hdma2d.Init.ColorMode = DMA2D_OUTPUT_RGB565;
  hdma2d.Init.OutputOffset = 0;
  hdma2d.LayerCfg[1].InputOffset = 0;
  hdma2d.LayerCfg[1].InputColorMode = DMA2D_INPUT_RGB565;
  hdma2d.LayerCfg[1].AlphaMode = DMA2D_NO_MODIF_ALPHA;
  hdma2d.LayerCfg[1].InputAlpha = 0;
  if (HAL_DMA2D_Init(&hdma2d) != HAL_OK)
  {
    Error_Handler();
  }
  if (HAL_DMA2D_ConfigLayer(&hdma2d, 1) != HAL_OK)
  {
    Error_Handler();
  }

}

static void MX_DSIHOST_DSI_Init(void)
{

  DSI_PLLInitTypeDef PLLInit = {0};
  DSI_HOST_TimeoutTypeDef HostTimeouts = {0};
  DSI_PHY_TimerTypeDef PhyTimings = {0};
  DSI_VidCfgTypeDef VidCfg = {0};

  hdsi.Instance = DSI;
  hdsi.Init.AutomaticClockLaneControl = DSI_AUTO_CLK_LANE_CTRL_DISABLE;
  hdsi.Init.TXEscapeCkdiv = 4;
  hdsi.Init.NumberOfLanes = DSI_TWO_DATA_LANES;
  PLLInit.PLLNDIV = 125;
  PLLInit.PLLIDF = DSI_PLL_IN_DIV2;
  PLLInit.PLLODF = DSI_PLL_OUT_DIV1;
  if (HAL_DSI_Init(&hdsi, &PLLInit) != HAL_OK)
  {
    Error_Handler();
  }
  HostTimeouts.TimeoutCkdiv = 1;
  HostTimeouts.HighSpeedTransmissionTimeout = 0;
  HostTimeouts.LowPowerReceptionTimeout = 0;
  HostTimeouts.HighSpeedReadTimeout = 0;
  HostTimeouts.LowPowerReadTimeout = 0;
  HostTimeouts.HighSpeedWriteTimeout = 0;
  HostTimeouts.HighSpeedWritePrespMode = DSI_HS_PM_DISABLE;
  HostTimeouts.LowPowerWriteTimeout = 0;
  HostTimeouts.BTATimeout = 0;
  if (HAL_DSI_ConfigHostTimeouts(&hdsi, &HostTimeouts) != HAL_OK)
  {
    Error_Handler();
  }
  PhyTimings.ClockLaneHS2LPTime = 35;
  PhyTimings.ClockLaneLP2HSTime = 35;
  PhyTimings.DataLaneHS2LPTime = 35;
  PhyTimings.DataLaneLP2HSTime = 35;
  PhyTimings.DataLaneMaxReadTime = 0;
  PhyTimings.StopWaitTime = 10;
  if (HAL_DSI_ConfigPhyTimer(&hdsi, &PhyTimings) != HAL_OK)
  {
    Error_Handler();
  }
  if (HAL_DSI_SetLowPowerRXFilter(&hdsi, 10000) != HAL_OK)
  {
    Error_Handler();
  }
  if (HAL_DSI_ConfigErrorMonitor(&hdsi, HAL_DSI_ERROR_NONE) != HAL_OK)
  {
    Error_Handler();
  }
  VidCfg.VirtualChannelID = 0;
  VidCfg.ColorCoding = DSI_RGB565;
  VidCfg.LooselyPacked = DSI_LOOSELY_PACKED_DISABLE;
  VidCfg.Mode = DSI_VID_MODE_BURST;
  VidCfg.PacketSize = 800;
  VidCfg.NumberOfChunks = 0;
  VidCfg.NullPacketSize = 0;
  VidCfg.HSPolarity = DSI_HSYNC_ACTIVE_HIGH;
  VidCfg.VSPolarity = DSI_VSYNC_ACTIVE_HIGH;
  VidCfg.DEPolarity = DSI_DATA_ENABLE_ACTIVE_HIGH;
  VidCfg.HorizontalSyncActive = 5;
  VidCfg.HorizontalBackPorch = 77;
  VidCfg.HorizontalLine = 1982;
  VidCfg.VerticalSyncActive = 120;
  VidCfg.VerticalBackPorch = 150;
  VidCfg.VerticalFrontPorch = 150;
  VidCfg.VerticalActive = 480;
  VidCfg.LPCommandEnable = DSI_LP_COMMAND_ENABLE;
  VidCfg.LPLargestPacketSize = 16;
  VidCfg.LPVACTLargestPacketSize = 0;
  VidCfg.LPHorizontalFrontPorchEnable = DSI_LP_HFP_ENABLE;
  VidCfg.LPHorizontalBackPorchEnable = DSI_LP_HBP_ENABLE;
  VidCfg.LPVerticalActiveEnable = DSI_LP_VACT_ENABLE;
  VidCfg.LPVerticalFrontPorchEnable = DSI_LP_VFP_ENABLE;
  VidCfg.LPVerticalBackPorchEnable = DSI_LP_VBP_ENABLE;
  VidCfg.LPVerticalSyncActiveEnable = DSI_LP_VSYNC_ENABLE;
  VidCfg.FrameBTAAcknowledgeEnable = DSI_FBTAA_DISABLE;
  if (HAL_DSI_ConfigVideoMode(&hdsi, &VidCfg) != HAL_OK)
  {
    Error_Handler();
  }
  if (HAL_DSI_SetGenericVCID(&hdsi, 0) != HAL_OK)
  {
    Error_Handler();
  }

}

static void MX_I2C1_Init(void)
{

  hi2c1.Instance = I2C1;
  hi2c1.Init.ClockSpeed = 100000;
  hi2c1.Init.DutyCycle = I2C_DUTYCYCLE_2;
  hi2c1.Init.OwnAddress1 = 0;
  hi2c1.Init.AddressingMode = I2C_ADDRESSINGMODE_7BIT;
  hi2c1.Init.DualAddressMode = I2C_DUALADDRESS_DISABLE;
  hi2c1.Init.OwnAddress2 = 0;
  hi2c1.Init.GeneralCallMode = I2C_GENERALCALL_DISABLE;
  hi2c1.Init.NoStretchMode = I2C_NOSTRETCH_DISABLE;
  if (HAL_I2C_Init(&hi2c1) != HAL_OK)
  {
    Error_Handler();
  }

}

static void MX_LTDC_Init(void)
{

  LTDC_LayerCfgTypeDef pLayerCfg = {0};

  hltdc.Instance = LTDC;
  hltdc.Init.HSPolarity = LTDC_HSPOLARITY_AH;
  hltdc.Init.VSPolarity = LTDC_VSPOLARITY_AH;
  hltdc.Init.DEPolarity = LTDC_DEPOLARITY_AL;
  hltdc.Init.PCPolarity = LTDC_PCPOLARITY_IPC;
  hltdc.Init.HorizontalSync = 1;
  hltdc.Init.VerticalSync = 119;
  hltdc.Init.AccumulatedHBP = 35;
  hltdc.Init.AccumulatedVBP = 269;
  hltdc.Init.AccumulatedActiveW = 835;
  hltdc.Init.AccumulatedActiveH = 749;
  hltdc.Init.TotalWidth = 869;
  hltdc.Init.TotalHeigh = 899;
  hltdc.Init.Backcolor.Blue = 0;
  hltdc.Init.Backcolor.Green = 0;
  hltdc.Init.Backcolor.Red = 0;
  if (HAL_LTDC_Init(&hltdc) != HAL_OK)
  {
    Error_Handler();
  }
  pLayerCfg.WindowX0 = 0;
  pLayerCfg.WindowX1 = 800;
  pLayerCfg.WindowY0 = 0;
  pLayerCfg.WindowY1 = 480;
  pLayerCfg.PixelFormat = LTDC_PIXEL_FORMAT_RGB565;
  pLayerCfg.Alpha = 255;
  pLayerCfg.Alpha0 = 0;
  pLayerCfg.BlendingFactor1 = LTDC_BLENDING_FACTOR1_PAxCA;
  pLayerCfg.BlendingFactor2 = LTDC_BLENDING_FACTOR2_PAxCA;
  pLayerCfg.FBStartAdress = 0xC0000000;
  pLayerCfg.ImageWidth = 800;
  pLayerCfg.ImageHeight = 480;
  pLayerCfg.Backcolor.Blue = 0;
  pLayerCfg.Backcolor.Green = 0;
  pLayerCfg.Backcolor.Red = 0;
  if (HAL_LTDC_ConfigLayer(&hltdc, &pLayerCfg, 0) != HAL_OK)
  {
    Error_Handler();
  }

}

static void MX_TIM3_Init(void)
{

  TIM_Encoder_InitTypeDef sConfig = {0};
  TIM_MasterConfigTypeDef sMasterConfig = {0};

  htim3.Instance = TIM3;
  htim3.Init.Prescaler = 0;
  htim3.Init.CounterMode = TIM_COUNTERMODE_UP;
  htim3.Init.Period = 65535;
  htim3.Init.ClockDivision = TIM_CLOCKDIVISION_DIV1;
  htim3.Init.AutoReloadPreload = TIM_AUTORELOAD_PRELOAD_DISABLE;
  sConfig.EncoderMode = TIM_ENCODERMODE_TI12;
  sConfig.IC1Polarity = TIM_ICPOLARITY_RISING;
  sConfig.IC1Selection = TIM_ICSELECTION_DIRECTTI;
  sConfig.IC1Prescaler = TIM_ICPSC_DIV1;
  sConfig.IC1Filter = 0;
  sConfig.IC2Polarity = TIM_ICPOLARITY_RISING;
  sConfig.IC2Selection = TIM_ICSELECTION_DIRECTTI;
  sConfig.IC2Prescaler = TIM_ICPSC_DIV1;
  sConfig.IC2Filter = 0;
  if (HAL_TIM_Encoder_Init(&htim3, &sConfig) != HAL_OK)
  {
    Error_Handler();
  }
  sMasterConfig.MasterOutputTrigger = TIM_TRGO_RESET;
  sMasterConfig.MasterSlaveMode = TIM_MASTERSLAVEMODE_DISABLE;
  if (HAL_TIMEx_MasterConfigSynchronization(&htim3, &sMasterConfig) != HAL_OK)
  {
    Error_Handler();
  }

}

static void MX_TIM5_Init(void)
{

  TIM_ClockConfigTypeDef sClockSourceConfig = {0};
  TIM_MasterConfigTypeDef sMasterConfig = {0};

  htim5.Instance = TIM5;
  htim5.Init.Prescaler = 0;
  htim5.Init.CounterMode = TIM_COUNTERMODE_UP;
  htim5.Init.Period = 4294967295;
  htim5.Init.ClockDivision = TIM_CLOCKDIVISION_DIV1;
  htim5.Init.AutoReloadPreload = TIM_AUTORELOAD_PRELOAD_DISABLE;
  if (HAL_TIM_Base_Init(&htim5) != HAL_OK)
  {
    Error_Handler();
  }
  sClockSourceConfig.ClockSource = TIM_CLOCKSOURCE_INTERNAL;
  if (HAL_TIM_ConfigClockSource(&htim5, &sClockSourceConfig) != HAL_OK)
  {
    Error_Handler();
  }
  sMasterConfig.MasterOutputTrigger = TIM_TRGO_RESET;
  sMasterConfig.MasterSlaveMode = TIM_MASTERSLAVEMODE_DISABLE;
  if (HAL_TIMEx_MasterConfigSynchronization(&htim5, &sMasterConfig) != HAL_OK)
  {
    Error_Handler();
  }

}

static void MX_TIM12_Init(void)
{

  TIM_ClockConfigTypeDef sClockSourceConfig = {0};
  TIM_OC_InitTypeDef sConfigOC = {0};

  htim12.Instance = TIM12;
  htim12.Init.Prescaler = 99;
  htim12.Init.CounterMode = TIM_COUNTERMODE_UP;
  htim12.Init.Period = 4096;
  htim12.Init.ClockDivision = TIM_CLOCKDIVISION_DIV1;
  htim12.Init.AutoReloadPreload = TIM_AUTORELOAD_PRELOAD_DISABLE;
  if (HAL_TIM_Base_Init(&htim12) != HAL_OK)
  {
    Error_Handler();
  }
  sClockSourceConfig.ClockSource = TIM_CLOCKSOURCE_INTERNAL;
  if (HAL_TIM_ConfigClockSource(&htim12, &sClockSourceConfig) != HAL_OK)
  {
    Error_Handler();
  }
  if (HAL_TIM_PWM_Init(&htim12) != HAL_OK)
  {
    Error_Handler();
  }
  sConfigOC.OCMode = TIM_OCMODE_PWM1;
  sConfigOC.Pulse = 0;
  sConfigOC.OCPolarity = TIM_OCPOLARITY_HIGH;
  sConfigOC.OCFastMode = TIM_OCFAST_DISABLE;
  if (HAL_TIM_PWM_ConfigChannel(&htim12, &sConfigOC, TIM_CHANNEL_1) != HAL_OK)
  {
    Error_Handler();
  }
  HAL_TIM_MspPostInit(&htim12);

}

static void MX_TIM14_Init(void)
{

  TIM_OC_InitTypeDef sConfigOC = {0};

  htim14.Instance = TIM14;
  htim14.Init.Prescaler = 99;
  htim14.Init.CounterMode = TIM_COUNTERMODE_UP;
  htim14.Init.Period = 4069;
  htim14.Init.ClockDivision = TIM_CLOCKDIVISION_DIV1;
  htim14.Init.AutoReloadPreload = TIM_AUTORELOAD_PRELOAD_DISABLE;
  if (HAL_TIM_Base_Init(&htim14) != HAL_OK)
  {
    Error_Handler();
  }
  if (HAL_TIM_PWM_Init(&htim14) != HAL_OK)
  {
    Error_Handler();
  }
  sConfigOC.OCMode = TIM_OCMODE_PWM1;
  sConfigOC.Pulse = 0;
  sConfigOC.OCPolarity = TIM_OCPOLARITY_HIGH;
  sConfigOC.OCFastMode = TIM_OCFAST_DISABLE;
  if (HAL_TIM_PWM_ConfigChannel(&htim14, &sConfigOC, TIM_CHANNEL_1) != HAL_OK)
  {
    Error_Handler();
  }
  HAL_TIM_MspPostInit(&htim14);

}

static void MX_USART3_UART_Init(void)
{

  huart3.Instance = USART3;
  huart3.Init.BaudRate = 115200;
  huart3.Init.WordLength = UART_WORDLENGTH_8B;
  huart3.Init.StopBits = UART_STOPBITS_1;
  huart3.Init.Parity = UART_PARITY_NONE;
  huart3.Init.Mode = UART_MODE_TX_RX;
  huart3.Init.HwFlowCtl = UART_HWCONTROL_NONE;
  huart3.Init.OverSampling = UART_OVERSAMPLING_16;
  if (HAL_UART_Init(&huart3) != HAL_OK)
  {
    Error_Handler();
  }

}

static void MX_DMA_Init(void)
{

  /* DMA controller clock enable */
  __HAL_RCC_DMA2_CLK_ENABLE();

  /* Configure DMA request hdma_memtomem_dma2_stream0 on DMA2_Stream0 */
  hdma_memtomem_dma2_stream0.Instance = DMA2_Stream0;
  hdma_memtomem_dma2_stream0.Init.Channel = DMA_CHANNEL_0;
  hdma_memtomem_dma2_stream0.Init.Direction = DMA_MEMORY_TO_MEMORY;
  hdma_memtomem_dma2_stream0.Init.PeriphInc = DMA_PINC_ENABLE;
  hdma_memtomem_dma2_stream0.Init.MemInc = DMA_MINC_ENABLE;
  hdma_memtomem_dma2_stream0.Init.PeriphDataAlignment = DMA_PDATAALIGN_WORD;
  hdma_memtomem_dma2_stream0.Init.MemDataAlignment = DMA_MDATAALIGN_WORD;
  hdma_memtomem_dma2_stream0.Init.Mode = DMA_NORMAL;
  hdma_memtomem_dma2_stream0.Init.Priority = DMA_PRIORITY_LOW;
  hdma_memtomem_dma2_stream0.Init.FIFOMode = DMA_FIFOMODE_ENABLE;
  hdma_memtomem_dma2_stream0.Init.FIFOThreshold = DMA_FIFO_THRESHOLD_FULL;
  hdma_memtomem_dma2_stream0.Init.MemBurst = DMA_MBURST_SINGLE;
  hdma_memtomem_dma2_stream0.Init.PeriphBurst = DMA_PBURST_SINGLE;
  if (HAL_DMA_Init(&hdma_memtomem_dma2_stream0) != HAL_OK)
  {
    Error_Handler( );
  }

  /* DMA interrupt init */
  /* DMA2_Stream0_IRQn interrupt configuration */
  HAL_NVIC_SetPriority(DMA2_Stream0_IRQn, 0, 0);
  HAL_NVIC_EnableIRQ(DMA2_Stream0_IRQn);
  /* DMA2_Stream4_IRQn interrupt configuration */
  HAL_NVIC_SetPriority(DMA2_Stream4_IRQn, 0, 0);
  HAL_NVIC_EnableIRQ(DMA2_Stream4_IRQn);

}

/* FMC initialization function */
static void MX_FMC_Init(void)
{

  /* USER CODE BEGIN FMC_Init 0 */
	static FMC_SDRAM_CommandTypeDef Command;
  /* USER CODE END FMC_Init 0 */

  FMC_SDRAM_TimingTypeDef SdramTiming = {0};

  /** Perform the SDRAM1 memory initialization sequence
  */
  hsdram1.Instance = FMC_SDRAM_DEVICE;
  /* hsdram1.Init */
  hsdram1.Init.SDBank = FMC_SDRAM_BANK1;
  hsdram1.Init.ColumnBitsNumber = FMC_SDRAM_COLUMN_BITS_NUM_8;
  hsdram1.Init.RowBitsNumber = FMC_SDRAM_ROW_BITS_NUM_12;
  hsdram1.Init.MemoryDataWidth = FMC_SDRAM_MEM_BUS_WIDTH_32;
  hsdram1.Init.InternalBankNumber = FMC_SDRAM_INTERN_BANKS_NUM_4;
  hsdram1.Init.CASLatency = FMC_SDRAM_CAS_LATENCY_3;
  hsdram1.Init.WriteProtection = FMC_SDRAM_WRITE_PROTECTION_DISABLE;
  hsdram1.Init.SDClockPeriod = FMC_SDRAM_CLOCK_PERIOD_2;
  hsdram1.Init.ReadBurst = FMC_SDRAM_RBURST_ENABLE;
  hsdram1.Init.ReadPipeDelay = FMC_SDRAM_RPIPE_DELAY_0;
  /* SdramTiming */
  SdramTiming.LoadToActiveDelay = 2;
  SdramTiming.ExitSelfRefreshDelay = 7;
  SdramTiming.SelfRefreshTime = 4;
  SdramTiming.RowCycleDelay = 7;
  SdramTiming.WriteRecoveryTime = 3;
  SdramTiming.RPDelay = 2;
  SdramTiming.RCDDelay = 2;

  if (HAL_SDRAM_Init(&hsdram1, &SdramTiming) != HAL_OK)
  {
    Error_Handler( );
  }

  /* USER CODE BEGIN FMC_Init 2 */

	/*
	 * The following code is copied from the STM32F469I-Disco Board Support Package
	 */
	__IO uint32_t tmpmrd = 0;

	/* Step 1: Configure a clock configuration enable command */
	Command.CommandMode            = FMC_SDRAM_CMD_CLK_ENABLE;
	Command.CommandTarget          = FMC_SDRAM_CMD_TARGET_BANK1;
	Command.AutoRefreshNumber      = 1;
	Command.ModeRegisterDefinition = 0;

	/* Send the command */
	HAL_SDRAM_SendCommand(&hsdram1, &Command, SDRAM_TIMEOUT);

	/* Step 2: Insert 100 us minimum delay */
	/* Inserted delay is equal to 1 ms due to systick time base unit (ms) */
	HAL_Delay(1);

	/* Step 3: Configure a PALL (precharge all) command */
	Command.CommandMode            = FMC_SDRAM_CMD_PALL;
	Command.CommandTarget          = FMC_SDRAM_CMD_TARGET_BANK1;
	Command.AutoRefreshNumber      = 1;
	Command.ModeRegisterDefinition = 0;

	/* Send the command */
	HAL_SDRAM_SendCommand(&hsdram1, &Command, SDRAM_TIMEOUT);

	/* Step 4: Configure an Auto Refresh command */
	Command.CommandMode            = FMC_SDRAM_CMD_AUTOREFRESH_MODE;
	Command.CommandTarget          = FMC_SDRAM_CMD_TARGET_BANK1;
	Command.AutoRefreshNumber      = 8;
	Command.ModeRegisterDefinition = 0;

	/* Send the command */
	HAL_SDRAM_SendCommand(&hsdram1, &Command, SDRAM_TIMEOUT);

	/* Step 5: Program the external memory mode register */
	tmpmrd = (uint32_t)SDRAM_MODEREG_BURST_LENGTH_1          |\
			SDRAM_MODEREG_BURST_TYPE_SEQUENTIAL   |\
			SDRAM_MODEREG_CAS_LATENCY_3           |\
			SDRAM_MODEREG_OPERATING_MODE_STANDARD |\
			SDRAM_MODEREG_WRITEBURST_MODE_SINGLE;

	Command.CommandMode            = FMC_SDRAM_CMD_LOAD_MODE;
	Command.CommandTarget          = FMC_SDRAM_CMD_TARGET_BANK1;
	Command.AutoRefreshNumber      = 1;
	Command.ModeRegisterDefinition = tmpmrd;

	/* Send the command */
	HAL_SDRAM_SendCommand(&hsdram1, &Command, SDRAM_TIMEOUT);

	/* Step 6: Set the refresh rate counter */
	/* Set the device refresh rate */
	HAL_SDRAM_ProgramRefreshRate(&hsdram1, REFRESH_COUNT);

  /* USER CODE END FMC_Init 2 */
}

static void MX_GPIO_Init(void)
{
  GPIO_InitTypeDef GPIO_InitStruct = {0};

  /* GPIO Ports Clock Enable */
  __HAL_RCC_GPIOE_CLK_ENABLE();
  __HAL_RCC_GPIOB_CLK_ENABLE();
  __HAL_RCC_GPIOA_CLK_ENABLE();
  __HAL_RCC_GPIOG_CLK_ENABLE();
  __HAL_RCC_GPIOD_CLK_ENABLE();
  __HAL_RCC_GPIOI_CLK_ENABLE();
  __HAL_RCC_GPIOF_CLK_ENABLE();
  __HAL_RCC_GPIOK_CLK_ENABLE();
  __HAL_RCC_GPIOH_CLK_ENABLE();
  __HAL_RCC_GPIOC_CLK_ENABLE();
  __HAL_RCC_GPIOJ_CLK_ENABLE();

  /*Configure GPIO pin Output Level */
  HAL_GPIO_WritePin(GPIOD, LED3_Pin|LED2_Pin, GPIO_PIN_RESET);

  /*Configure GPIO pin Output Level */
  HAL_GPIO_WritePin(LED4_GPIO_Port, LED4_Pin, GPIO_PIN_RESET);

  /*Configure GPIO pin Output Level */
  HAL_GPIO_WritePin(LED1_GPIO_Port, LED1_Pin, GPIO_PIN_RESET);

  /*Configure GPIO pin Output Level */
  HAL_GPIO_WritePin(GPIOB, OTG_FS1_PowerSwitchOn_Pin|EXT_RESET_Pin, GPIO_PIN_RESET);

  /*Configure GPIO pin Output Level */
  HAL_GPIO_WritePin(GPIOH, GPIO_PIN_7, GPIO_PIN_RESET);

  /*Configure GPIO pins : LED3_Pin LED2_Pin */
  GPIO_InitStruct.Pin = LED3_Pin|LED2_Pin;
  GPIO_InitStruct.Mode = GPIO_MODE_OUTPUT_OD;
  GPIO_InitStruct.Pull = GPIO_NOPULL;
  GPIO_InitStruct.Speed = GPIO_SPEED_FREQ_LOW;
  HAL_GPIO_Init(GPIOD, &GPIO_InitStruct);

  /*Configure GPIO pin : LED4_Pin */
  GPIO_InitStruct.Pin = LED4_Pin;
  GPIO_InitStruct.Mode = GPIO_MODE_OUTPUT_OD;
  GPIO_InitStruct.Pull = GPIO_NOPULL;
  GPIO_InitStruct.Speed = GPIO_SPEED_FREQ_LOW;
  HAL_GPIO_Init(LED4_GPIO_Port, &GPIO_InitStruct);

  /*Configure GPIO pin : LED1_Pin */
  GPIO_InitStruct.Pin = LED1_Pin;
  GPIO_InitStruct.Mode = GPIO_MODE_OUTPUT_OD;
  GPIO_InitStruct.Pull = GPIO_NOPULL;
  GPIO_InitStruct.Speed = GPIO_SPEED_FREQ_LOW;
  HAL_GPIO_Init(LED1_GPIO_Port, &GPIO_InitStruct);

  /*Configure GPIO pins : OTG_FS1_PowerSwitchOn_Pin EXT_RESET_Pin */
  GPIO_InitStruct.Pin = OTG_FS1_PowerSwitchOn_Pin|EXT_RESET_Pin;
  GPIO_InitStruct.Mode = GPIO_MODE_OUTPUT_PP;
  GPIO_InitStruct.Pull = GPIO_NOPULL;
  GPIO_InitStruct.Speed = GPIO_SPEED_FREQ_LOW;
  HAL_GPIO_Init(GPIOB, &GPIO_InitStruct);

  /*Configure GPIO pin : LCD_INT_Pin */
  GPIO_InitStruct.Pin = LCD_INT_Pin;
  GPIO_InitStruct.Mode = GPIO_MODE_IT_RISING;
  GPIO_InitStruct.Pull = GPIO_NOPULL;
  HAL_GPIO_Init(LCD_INT_GPIO_Port, &GPIO_InitStruct);

  /*Configure GPIO pin : PH7 */
  GPIO_InitStruct.Pin = GPIO_PIN_7;
  GPIO_InitStruct.Mode = GPIO_MODE_OUTPUT_PP;
  GPIO_InitStruct.Pull = GPIO_NOPULL;
  GPIO_InitStruct.Speed = GPIO_SPEED_FREQ_LOW;
  HAL_GPIO_Init(GPIOH, &GPIO_InitStruct);

}

/* USER CODE BEGIN 4 */

int _write(int file, char *ptr, int len)
{
	HAL_UART_Transmit(&huart3, (const uint8_t *)ptr, len, 100);
	return len;
}

//static lv_obj_t * btn1;
//static lv_obj_t * btn2;

static lv_obj_t * chart;
static lv_chart_series_t * ser_rpm;
static lv_chart_series_t * ser_setPoint;
//static lv_obj_t * kb;
//static lv_obj_t * ta_setPoint;
//static lv_obj_t * ta_kP;
//static lv_obj_t * ta_kI;
//static lv_obj_t * ta_kD;

//static lv_obj_t * l_error;
static lv_obj_t * l_duty;
//static lv_obj_t * l_P;
//static lv_obj_t * l_I;
//static lv_obj_t * l_D;
static lv_obj_t * l_RPM;

//static char str_error[10] 	= {"0"};
static char str_duty[16] 	= {"0"};
//static char str_P[10] 		= {"0"};
//static char str_I[10] 		= {"0"};
//static char str_D[10] 		= {"0"};
static char str_RPM[16] 	= {"0"};

typedef union
{
    unsigned int Val;
    struct
    {
        unsigned Flag:1;        // flag of filling of summ
        unsigned Index:9;       // buffer index
        unsigned Filter_sum:23; // summ of filter's value
    } Reg;
} FILTER_REG;

#define COUNT_FILTER	4

uint16_t  filter_average(uint16_t ADC_val, uint16_t* buf, FILTER_REG* filter_reg){

    if (filter_reg -> Reg.Flag){
        filter_reg -> Reg.Filter_sum -= buf[filter_reg -> Reg.Index];
        filter_reg -> Reg.Filter_sum += ADC_val;
        buf[filter_reg -> Reg.Index] = ADC_val;
        if (filter_reg -> Reg.Index >= COUNT_FILTER - 1){
            filter_reg -> Reg.Index = 0;
        }
        else{
            filter_reg -> Reg.Index++;
        }
    }
    else{
        filter_reg -> Reg.Filter_sum += ADC_val;
        buf[filter_reg -> Reg.Index] = ADC_val;
        if (filter_reg -> Reg.Index >= COUNT_FILTER - 1){
            filter_reg -> Reg.Index = 0;
            filter_reg -> Reg.Flag = 1;
        }
        else{
            filter_reg -> Reg.Index++;
        }
    }
    return (filter_reg -> Reg.Filter_sum / COUNT_FILTER);
}

uint16_t buffADC1[COUNT_FILTER], buffADC2[COUNT_FILTER];
FILTER_REG filterADC1, filterADC2;
static uint16_t ADC1_voltage, ADC2_voltage;

void chartUpdate(lv_timer_t * tmr)
{

	ADC1_voltage = filter_average((uint16_t)(ADC_DATA[0]), buffADC1, &filterADC1);
	ADC2_voltage = filter_average((uint16_t)(ADC_DATA[1]), buffADC2, &filterADC2);

	mA1 = ((ADC1_voltage * 3.3)/4096)/(100*0.1)*1000.0;
	mA2 = ((ADC2_voltage * 3.3)/4096)/(100*0.1)*1000.0;

	lv_chart_set_next_value(chart, ser_rpm,  (lv_coord_t)mA1);
	lv_chart_set_next_value(chart, ser_setPoint, (lv_coord_t)mA2);

//	static int i = 0;
//	if(i++ >= 5)
//	{
		sprintf(str_RPM, "%.3f mA", mA1);
		sprintf(str_duty, "%.3f mA", mA2);

		size_t l = sprintf(string, "$%0.3f %0.3f;", mA1, mA2);
		/* Transmite via usb a linha gerada para o supervisório */
		CDC_Transmit_FS((uint8_t*)string, l);

//		sprintf(str_error, "%.2f", error);
//		sprintf(str_P, "%.2f", P);
//		sprintf(str_I, "%.2f", I);
//		sprintf(str_D, "%.2f", D);
//
		lv_label_set_text_static(l_RPM, str_RPM);
		lv_label_set_text_static(l_duty, str_duty);
//		lv_label_set_text_static(l_error, str_error);
//		lv_label_set_text_static(l_P, str_P);
//		lv_label_set_text_static(l_I, str_I);
//		lv_label_set_text_static(l_D, str_D);
//	}
}

//static void event_handler(lv_event_t * e)
//{
//	lv_event_code_t code = lv_event_get_code(e);
//	lv_obj_t * bt = lv_event_get_target(e);
//
//	if(code == LV_EVENT_CLICKED)
//	{
//		if(bt == btn1)
//		{
//			setPoint = atof(lv_textarea_get_text(ta_setPoint));
//			kP = atof(lv_textarea_get_text(ta_kP));
//			kI = atof(lv_textarea_get_text(ta_kI));
//			kD = atof(lv_textarea_get_text(ta_kD));
//		}
//		else
//		{
//			P = 0.0;
//			I = 0.0;
//			D = 0.0;
//			PID = 0.0;
//			setPoint 	= 0.0;
//			error 	= 0.0;
//			lastRPM	= 0.0;
//			RPM = 0;
//			TIM14->CCR1 = 0;
//		}
//	}
//}

//static void ta_event_cb(lv_event_t * e)
//{
//	lv_obj_t * ta = lv_event_get_target(e);
//
//	if(e->code == LV_EVENT_FOCUSED)
//	{
//		if(lv_obj_has_flag(kb, LV_OBJ_FLAG_HIDDEN))
//		{
//			lv_obj_clear_flag(kb, LV_OBJ_FLAG_HIDDEN);
//		}
//		lv_keyboard_set_textarea(kb, ta);
//	}
//	else if(e->code == LV_EVENT_DEFOCUSED)
//	{
//		lv_obj_add_flag(kb, LV_OBJ_FLAG_HIDDEN);
//	}
//}

void create_gui(void)
{
	//lv_obj_t * label;
//	btn1 = lv_btn_create(lv_scr_act());
//	lv_obj_add_event_cb(btn1, event_handler, LV_EVENT_ALL, NULL);
//	lv_obj_set_pos(btn1, 636, 25);
//	lv_obj_set_size(btn1, 100, 60);
//
//	label = lv_label_create(btn1);
//	lv_label_set_text(label, "Start");
//	lv_obj_center(label);
//
//	btn2 = lv_btn_create(lv_scr_act());
//	lv_obj_add_event_cb(btn2, event_handler, LV_EVENT_ALL, NULL);
//	lv_obj_set_pos(btn2, 636, 125);
//	lv_obj_set_size(btn2, 100, 60);
//
//	label = lv_label_create(btn2);
//	lv_label_set_text(label, "Reset");
//	lv_obj_center(label);

	/*Create a chart*/
	chart = lv_chart_create(lv_scr_act());
	lv_obj_set_size(chart, 720, 400);
	lv_obj_align(chart, LV_ALIGN_BOTTOM_MID, 20, -30);

	lv_chart_set_point_count(chart, 200);
	lv_chart_set_range(chart, LV_CHART_AXIS_PRIMARY_Y, -10, 50);
	lv_chart_set_range(chart, LV_CHART_AXIS_SECONDARY_Y, 0, 200);

	lv_chart_set_axis_tick(chart, LV_CHART_AXIS_PRIMARY_Y, 10, 5, 7, 5, true, 40);
	lv_chart_set_axis_tick(chart, LV_CHART_AXIS_PRIMARY_X, 5, 5, 20, 5, true, 40);

	lv_chart_set_update_mode(chart, LV_CHART_UPDATE_MODE_CIRCULAR);

	lv_obj_refresh_ext_draw_size(chart);

	ser_rpm = lv_chart_add_series(chart, lv_palette_main(LV_PALETTE_RED), LV_CHART_AXIS_PRIMARY_X);
	ser_setPoint = lv_chart_add_series(chart, lv_palette_main(LV_PALETTE_BLUE), LV_CHART_AXIS_PRIMARY_X);

	lv_chart_set_zoom_x(chart, 250);

	lv_timer_create(chartUpdate, 80, NULL);

//	lv_obj_t * l = lv_label_create(lv_scr_act());
//	lv_label_set_text(l, "SetPoint:");
//	lv_obj_set_pos(l, 8, 18);
//
//	ta_setPoint = lv_textarea_create(lv_scr_act());
//	lv_textarea_set_text(ta_setPoint, "0.0");
//	lv_obj_set_pos(ta_setPoint, 80, 5);
//	lv_obj_set_size(ta_setPoint, 120, 42);
//	lv_obj_add_event_cb(ta_setPoint, ta_event_cb, LV_EVENT_ALL, NULL);
//
//	l = lv_label_create(lv_scr_act());
//	lv_label_set_text(l, "kP:");
//	lv_obj_set_pos(l, 8, 63 );
//
//	ta_kP = lv_textarea_create(lv_scr_act());
//	lv_textarea_set_text(ta_kP, "1.0");
//	lv_obj_set_pos(ta_kP, 80, 52);
//	lv_obj_set_size(ta_kP, 120, 42);
//	lv_obj_add_event_cb(ta_kP, ta_event_cb, LV_EVENT_ALL, NULL);
//
//	l = lv_label_create(lv_scr_act());
//	lv_label_set_text(l, "kI:");
//	lv_obj_set_pos(l, 8, 110 );
//
//	ta_kI = lv_textarea_create(lv_scr_act());
//	lv_textarea_set_text(ta_kI, "1.0");
//
//	lv_obj_set_pos(ta_kI, 80, 99);
//	lv_obj_set_size(ta_kI, 120, 42);
//	lv_obj_add_event_cb(ta_kI, ta_event_cb, LV_EVENT_ALL, NULL);
//
//	l = lv_label_create(lv_scr_act());
//	lv_label_set_text(l, "kD:");
//	lv_obj_set_pos(l, 8, 152 );
//
//	ta_kD = lv_textarea_create(lv_scr_act());
//	lv_textarea_set_text(ta_kD, "0.0");
//	lv_obj_set_pos(ta_kD, 80, 146);
//	lv_obj_set_size(ta_kD, 120, 42);
//	lv_obj_add_event_cb(ta_kD, ta_event_cb, LV_EVENT_ALL, NULL);
//
//	/*Create a keyboard*/
//	kb = lv_keyboard_create(lv_scr_act());
//	lv_obj_set_size(kb,  LV_HOR_RES, LV_VER_RES / 2);
//	lv_keyboard_set_mode(kb, LV_KEYBOARD_MODE_NUMBER);
//
//	lv_obj_add_flag(kb, LV_OBJ_FLAG_HIDDEN);

	lv_obj_t * l = lv_label_create(lv_scr_act());
	lv_label_set_text(l, "Corrente 1:");
	lv_obj_set_pos(l, 100, 20 );

	l = lv_label_create(lv_scr_act());
	lv_label_set_text(l, "Corrente 2:");
	lv_obj_set_pos(l, 300, 20 );

//	l = lv_label_create(lv_scr_act());
//	lv_label_set_text(l, "Erro:");
//	lv_obj_set_pos(l, 360, 81 );
//
//	l = lv_label_create(lv_scr_act());
//	lv_label_set_text(l, "P:");
//	lv_obj_set_pos(l, 360, 112 );
//
//	l = lv_label_create(lv_scr_act());
//	lv_label_set_text(l, "I:");
//	lv_obj_set_pos(l, 360, 142 );
//
//	l = lv_label_create(lv_scr_act());
//	lv_label_set_text(l, "D:");
//	lv_obj_set_pos(l, 360, 172 );
//
	l_RPM = lv_label_create(lv_scr_act());
	lv_label_set_text_static(l_RPM, str_RPM);
	lv_obj_set_pos(l_RPM, 190, 20 );

	l_duty = lv_label_create(lv_scr_act());
	lv_label_set_text_static(l_duty, str_duty);
	lv_obj_set_pos(l_duty, 390, 20 );
//
//	l_error = lv_label_create(lv_scr_act());
//	lv_label_set_text_static(l_error, str_error);
//	lv_obj_set_pos(l_error, 403, 81 );
//
//	l_P = lv_label_create(lv_scr_act());
//	lv_label_set_text_static(l_P, str_P);
//	lv_obj_set_pos(l_P, 403, 112 );
//
//	l_I = lv_label_create(lv_scr_act());
//	lv_label_set_text_static(l_I, str_I);
//	lv_obj_set_pos(l_I, 403, 142 );
//
//	l_D = lv_label_create(lv_scr_act());
//	lv_label_set_text_static(l_D, str_D);
//	lv_obj_set_pos(l_D, 403, 172 );
}

/* USER CODE END 4 */

void Error_Handler(void)
{
	__disable_irq();
	while (1)
	{
	}
}
